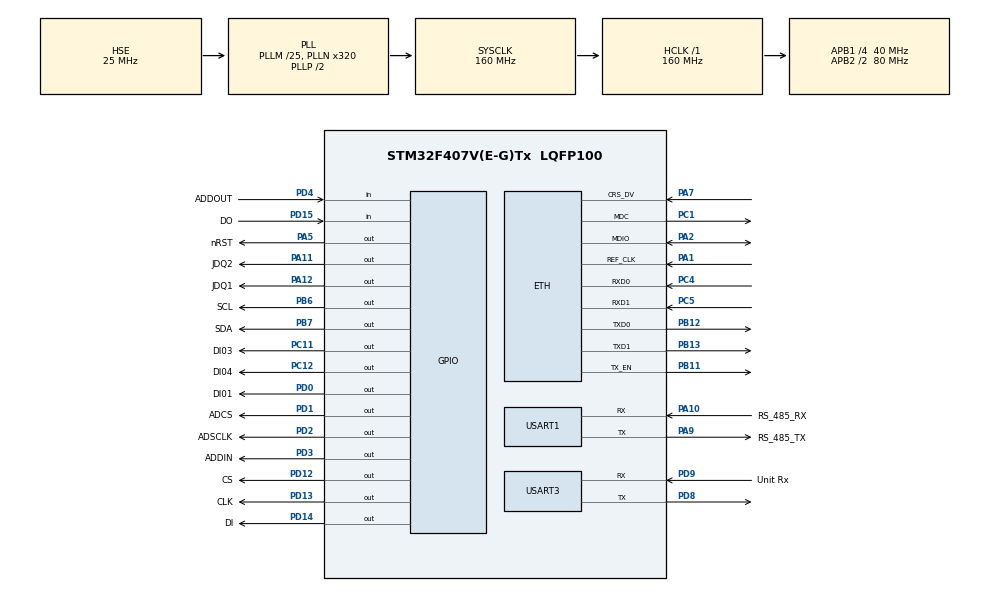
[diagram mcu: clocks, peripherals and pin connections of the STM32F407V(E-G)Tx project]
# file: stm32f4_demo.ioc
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Dma.Request0=USART1_RX
Dma.Request1=USART1_TX
Dma.Request2=USART3_RX
Dma.Request3=USART3_TX
Dma.USART1_RX.0.Direction=DMA_PERIPH_TO_MEMORY
Dma.USART1_RX.0.FIFOMode=DMA_FIFOMODE_DISABLE
Dma.USART1_RX.0.Instance=DMA2_Stream2
Dma.USART1_RX.0.MemDataAlignment=DMA_MDATAALIGN_BYTE
Dma.USART1_RX.0.MemInc=DMA_MINC_ENABLE
Dma.USART1_RX.0.Mode=DMA_NORMAL
Dma.USART1_RX.0.PeriphDataAlignment=DMA_PDATAALIGN_BYTE
Dma.USART1_RX.0.PeriphInc=DMA_PINC_DISABLE
Dma.USART1_RX.0.Priority=DMA_PRIORITY_HIGH
Dma.USART1_TX.1.Direction=DMA_MEMORY_TO_PERIPH
Dma.USART1_TX.1.FIFOMode=DMA_FIFOMODE_DISABLE
Dma.USART1_TX.1.Instance=DMA2_Stream7
Dma.USART1_TX.1.MemDataAlignment=DMA_MDATAALIGN_BYTE
Dma.USART1_TX.1.MemInc=DMA_MINC_ENABLE
Dma.USART1_TX.1.Mode=DMA_NORMAL
Dma.USART1_TX.1.PeriphDataAlignment=DMA_PDATAALIGN_BYTE
Dma.USART1_TX.1.PeriphInc=DMA_PINC_DISABLE
Dma.USART1_TX.1.Priority=DMA_PRIORITY_HIGH
Dma.USART3_RX.2.Direction=DMA_PERIPH_TO_MEMORY
Dma.USART3_RX.2.FIFOMode=DMA_FIFOMODE_DISABLE
Dma.USART3_RX.2.Instance=DMA1_Stream1
Dma.USART3_RX.2.MemDataAlignment=DMA_MDATAALIGN_BYTE
Dma.USART3_RX.2.MemInc=DMA_MINC_ENABLE
Dma.USART3_RX.2.Mode=DMA_NORMAL
Dma.USART3_RX.2.PeriphDataAlignment=DMA_PDATAALIGN_BYTE
Dma.USART3_RX.2.PeriphInc=DMA_PINC_DISABLE
Dma.USART3_RX.2.Priority=DMA_PRIORITY_HIGH
Dma.USART3_TX.3.Direction=DMA_MEMORY_TO_PERIPH
Dma.USART3_TX.3.FIFOMode=DMA_FIFOMODE_DISABLE
Dma.USART3_TX.3.Instance=DMA1_Stream3
Dma.USART3_TX.3.MemDataAlignment=DMA_MDATAALIGN_BYTE
Dma.USART3_TX.3.MemInc=DMA_MINC_ENABLE
Dma.USART3_TX.3.Mode=DMA_NORMAL
Dma.USART3_TX.3.PeriphDataAlignment=DMA_PDATAALIGN_BYTE
Dma.USART3_TX.3.PeriphInc=DMA_PINC_DISABLE
Dma.USART3_TX.3.Priority=DMA_PRIORITY_HIGH
ETH.MediaInterface=ETH_MEDIA_INTERFACE_RMII
ETH.PHY_Name_RMII=userPHY
ETH.PhyAddress=1
FREERTOS.Tasks01=defaultTask,0,128,StartDefaultTask,Default,NULL
IWDG.Prescaler=IWDG_PRESCALER_64
IWDG.Reload=0xFFF
LWIP.CHECKSUM_BY_HARDWARE=1
LWIP.CHECKSUM_GEN_UDP=0
LWIP.LWIP_CHECKSUM_CTRL_PER_NETIF=0
LWIP.LWIP_DHCP=1
LWIP.LWIP_DNS=1
LWIP.LWIP_NETIF_LINK_CALLBACK=1
LWIP.LWIP_NETIF_STATUS_CALLBACK=1
LWIP.Version=v2.0.3_Cube
Mcu.Family=STM32F4
Mcu.Name=STM32F407V(E-G)Tx
Mcu.Package=LQFP100
NVIC.DMA1_Stream1_IRQn=true\:5\:0\:false\:false\:true\:true\:false\:true
NVIC.DMA1_Stream3_IRQn=true\:5\:0\:false\:false\:true\:true\:false\:true
NVIC.DMA2_Stream2_IRQn=true\:5\:0\:false\:false\:true\:true\:false\:true
NVIC.DMA2_Stream7_IRQn=true\:5\:0\:false\:false\:true\:true\:false\:true
NVIC.ETH_IRQn=true\:5\:0\:false\:false\:true\:true\:true\:true
NVIC.PriorityGroup=NVIC_PRIORITYGROUP_4
NVIC.TIM6_DAC_IRQn=true\:0\:0\:false\:false\:true\:false\:false\:true
NVIC.TimeBase=TIM6_DAC_IRQn
NVIC.TimeBaseIP=TIM6
NVIC.USART1_IRQn=true\:5\:0\:false\:false\:true\:true\:true\:true
NVIC.USART3_IRQn=true\:5\:0\:false\:false\:true\:true\:true\:true
PA1.Mode=RMII
PA1.Signal=ETH_REF_CLK
PA10.GPIO_Label=RS_485_RX
PA10.Mode=Asynchronous
PA10.Signal=USART1_RX
PA11.GPIO_Label=JDQ2
PA11.Signal=GPIO_Output
PA12.GPIO_Label=JDQ1
PA12.Signal=GPIO_Output
PA13.Mode=Serial_Wire
PA13.Signal=SYS_JTMS-SWDIO
PA14.Mode=Serial_Wire
PA14.Signal=SYS_JTCK-SWCLK
PA2.Mode=RMII
PA2.Signal=ETH_MDIO
PA5.GPIO_Label=nRST
PA5.Signal=GPIO_Output
PA7.Mode=RMII
PA7.Signal=ETH_CRS_DV
PA9.GPIO_Label=RS_485_TX
PA9.Mode=Asynchronous
PA9.Signal=USART1_TX
PB11.Mode=RMII
PB11.Signal=ETH_TX_EN
PB12.Mode=RMII
PB12.Signal=ETH_TXD0
PB13.Mode=RMII
PB13.Signal=ETH_TXD1
PB14.Signal=USB_OTG_HS_DM
PB15.Signal=USB_OTG_HS_DP
PB6.GPIO_Label=SCL
PB6.Signal=GPIO_Output
PB7.GPIO_Label=SDA
PB7.Signal=GPIO_Output
PC1.Mode=RMII
PC1.Signal=ETH_MDC
PC11.GPIO_Label=DI03
PC11.Signal=GPIO_Output
PC12.GPIO_Label=DI04
PC12.Signal=GPIO_Output
PC4.Mode=RMII
PC4.Signal=ETH_RXD0
PC5.Mode=RMII
PC5.Signal=ETH_RXD1
PD0.GPIO_Label=DI01
PD0.Signal=GPIO_Output
PD1.GPIO_Label=ADCS
PD1.Signal=GPIO_Output
PD12.GPIO_Label=CS
PD12.Signal=GPIO_Output
PD13.GPIO_Label=CLK
PD13.Signal=GPIO_Output
PD14.GPIO_Label=DI
PD14.Signal=GPIO_Output
PD15.GPIO_Label=DO
PD15.Signal=GPIO_Input
PD2.GPIO_Label=ADSCLK
PD2.Signal=GPIO_Output
PD3.GPIO_Label=ADDIN
PD3.Signal=GPIO_Output
PD4.GPIO_Label=ADDOUT
PD4.Signal=GPIO_Input
PD8.Mode=Asynchronous
PD8.Signal=USART3_TX
PD9.GPIO_Label=Unit Rx
PD9.Mode=Asynchronous
PD9.Signal=USART3_RX
PH0-OSC_IN.Mode=HSE-External-Oscillator
PH0-OSC_IN.Signal=RCC_OSC_IN
PH1-OSC_OUT.Mode=HSE-External-Oscillator
PH1-OSC_OUT.Signal=RCC_OSC_OUT
ProjectManager.HeapSize=0x200
ProjectManager.StackSize=0x400
ProjectManager.TargetToolchain=MDK-ARM V5
RCC.48MHZClocksFreq_Value=80000000
RCC.AHBFreq_Value=160000000
RCC.APB1CLKDivider=RCC_HCLK_DIV4
RCC.APB1Freq_Value=40000000
RCC.APB1TimFreq_Value=80000000
RCC.APB2CLKDivider=RCC_HCLK_DIV2
RCC.APB2Freq_Value=80000000
RCC.APB2TimFreq_Value=160000000
RCC.CortexFreq_Value=160000000
RCC.HCLKFreq_Value=160000000
RCC.HSE_VALUE=25000000
RCC.HSI_VALUE=16000000
RCC.LSE_VALUE=32768
RCC.PLLM=25
RCC.PLLN=320
RCC.PLLSourceVirtual=RCC_PLLSOURCE_HSE
RCC.SYSCLKFreq_VALUE=160000000
RCC.SYSCLKSource=RCC_SYSCLKSOURCE_PLLCLK
RCC.VCOOutputFreq_Value=320000000
USART1.VirtualMode=VM_ASYNC
USART3.VirtualMode=VM_ASYNC
VP_CRC_VS_CRC.Mode=CRC_Activate
VP_FREERTOS_VS_CMSIS_V1.Mode=CMSIS_V1
VP_IWDG_VS_IWDG.Mode=IWDG_Activate
VP_LWIP_VS_Enabled.Mode=Enabled
VP_SYS_VS_tim6.Mode=TIM6
board=custom

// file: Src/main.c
/* USER CODE BEGIN Header */
/**
  ******************************************************************************
  * @file           : main.c
  * @brief          : Main program body
  ******************************************************************************
  * @attention
  *
  * <h2><center>&copy; Copyright (c) 2020 STMicroelectronics.
  * All rights reserved.</center></h2>
  *
  * This software component is licensed by ST under Ultimate Liberty license
  * SLA0044, the "License"; You may not use this file except in compliance with
  * the License. You may obtain a copy of the License at:
  *                             www.st.com/SLA0044
  *
  ******************************************************************************
  */
/* USER CODE END Header */

#include "main.h"
#include "cmsis_os.h"
#include "crc.h"
#include "dma.h"
#include "iwdg.h"
#include "lwip.h"
#include "usart.h"
#include "gpio.h"

/* USER CODE BEGIN Includes */
#include "SYS_include.h"
/* USER CODE END Includes */

/* USER CODE BEGIN PV */
osThreadId app_TaskHandle;
/* USER CODE END PV */

void SystemClock_Config(void);
void MX_FREERTOS_Init(void);
/* USER CODE BEGIN PFP */

void app_main(void const * argument);

/* USER CODE END PFP */

int main(void)
{

  /* MCU Configuration--------------------------------------------------------*/

  /* Reset of all peripherals, Initializes the Flash interface and the Systick. */
  HAL_Init();

  /* Configure the system clock */
  SystemClock_Config();

  /* Initialize all configured peripherals */
  MX_GPIO_Init();
  MX_DMA_Init();
  MX_CRC_Init();
  //MX_IWDG_Init();
  MX_USART1_UART_Init();
  MX_USART3_UART_Init();

  /* Call init function for freertos objects (in freertos.c) */
  MX_FREERTOS_Init();

  /* Start scheduler */
  osKernelStart();

  /* We should never get here as control is now taken by the scheduler */

  /* Infinite loop */
  while (1)
  {

  }
}

void SystemClock_Config(void)
{
  RCC_OscInitTypeDef RCC_OscInitStruct = {0};
  RCC_ClkInitTypeDef RCC_ClkInitStruct = {0};

  /** Configure the main internal regulator output voltage
  */
  __HAL_RCC_PWR_CLK_ENABLE();
  __HAL_PWR_VOLTAGESCALING_CONFIG(PWR_REGULATOR_VOLTAGE_SCALE1);
  /** Initializes the CPU, AHB and APB busses clocks
  */
  RCC_OscInitStruct.OscillatorType = RCC_OSCILLATORTYPE_LSI|RCC_OSCILLATORTYPE_HSE;
  RCC_OscInitStruct.HSEState = RCC_HSE_ON;
  RCC_OscInitStruct.LSIState = RCC_LSI_ON;
  RCC_OscInitStruct.PLL.PLLState = RCC_PLL_ON;
  RCC_OscInitStruct.PLL.PLLSource = RCC_PLLSOURCE_HSE;
  RCC_OscInitStruct.PLL.PLLM = 25;
  RCC_OscInitStruct.PLL.PLLN = 320;
  RCC_OscInitStruct.PLL.PLLP = RCC_PLLP_DIV2;
  RCC_OscInitStruct.PLL.PLLQ = 4;
  if (HAL_RCC_OscConfig(&RCC_OscInitStruct) != HAL_OK)
  {
    Error_Handler();
  }
  /** Initializes the CPU, AHB and APB busses clocks
  */
  RCC_ClkInitStruct.ClockType = RCC_CLOCKTYPE_HCLK|RCC_CLOCKTYPE_SYSCLK
                              |RCC_CLOCKTYPE_PCLK1|RCC_CLOCKTYPE_PCLK2;
  RCC_ClkInitStruct.SYSCLKSource = RCC_SYSCLKSOURCE_PLLCLK;
  RCC_ClkInitStruct.AHBCLKDivider = RCC_SYSCLK_DIV1;
  RCC_ClkInitStruct.APB1CLKDivider = RCC_HCLK_DIV4;
  RCC_ClkInitStruct.APB2CLKDivider = RCC_HCLK_DIV2;

  if (HAL_RCC_ClockConfig(&RCC_ClkInitStruct, FLASH_LATENCY_5) != HAL_OK)
  {
    Error_Handler();
  }
}

/* USER CODE BEGIN 4 */

void app_main(void const *argument)
{
  static int num_cnt;
  for(;;)
  {
    //HAL_IWDG_Refresh(&hiwdg);
    num_cnt++;
    dbg_msg("Hello CMSIS-RTOS %d\r\n",num_cnt);
    osDelay(1000);
  }
}

/* USER CODE END 4 */

void HAL_TIM_PeriodElapsedCallback(TIM_HandleTypeDef *htim)
{
  if (htim->Instance == TIM6) {
    HAL_IncTick();
  }
}

void Error_Handler(void)
{
}

/************************ (C) COPYRIGHT STMicroelectronics *****END OF FILE****/

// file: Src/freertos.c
/* USER CODE BEGIN Header */
/**
  ******************************************************************************
  * File Name          : freertos.c
  * Description        : Code for freertos applications
  ******************************************************************************
  * @attention
  *
  * <h2><center>&copy; Copyright (c) 2020 STMicroelectronics.
  * All rights reserved.</center></h2>
  *
  * This software component is licensed by ST under Ultimate Liberty license
  * SLA0044, the "License"; You may not use this file except in compliance with
  * the License. You may obtain a copy of the License at:
  *                             www.st.com/SLA0044
  *
  ******************************************************************************
  */
/* USER CODE END Header */

#include "FreeRTOS.h"
#include "task.h"
#include "main.h"
#include "cmsis_os.h"

osThreadId defaultTaskHandle;

void StartDefaultTask(void const * argument);

extern void MX_LWIP_Init(void);
void MX_FREERTOS_Init(void); /* (MISRA C 2004 rule 8.1) */

void MX_FREERTOS_Init(void) {

  /* Create the thread(s) */
  /* definition and creation of defaultTask */
  osThreadDef(defaultTask, StartDefaultTask, osPriorityNormal, 0, 128);
  defaultTaskHandle = osThreadCreate(osThread(defaultTask), NULL);

}

void StartDefaultTask(void const * argument)
{
  /* init code for LWIP */
  MX_LWIP_Init();

  for(;;)
  {
    osDelay(1);
  }
}

/************************ (C) COPYRIGHT STMicroelectronics *****END OF FILE****/
